AUTOSAR XML (schema 4-2-2)
package /Components
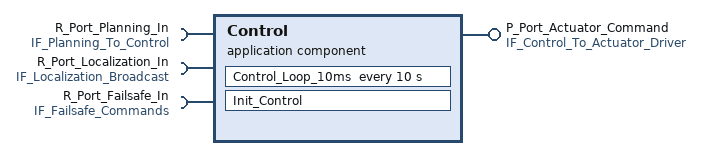
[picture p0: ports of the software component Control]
  application sw component type Control
    provide port P_Port_Actuator_Command: provided-interface=IF_Control_To_Actuator_Driver
    require port R_Port_Planning_In: required-interface=IF_Planning_To_Control
    require port R_Port_Localization_In: required-interface=IF_Localization_Broadcast
    require port R_Port_Failsafe_In: required-interface=IF_Failsafe_Commands
    behavior Control_InternalBehavior
      init event Control_Init: start-on-event=Init_Control
      timing event Control_10ms: start-on-event=Control_Loop_10ms, period=10
      runnable Init_Control: symbol=Init_Control_Symbol
        data-receive-point-by-arguments:
          access Init_Read_Behavior_Cmd: accessed-variable={autosar-variable-in-impl-datatype={port-prototype=R_Port_Planning_In, target-data-prototype=ImplType_Behavior_Cmd_Init}, autosar-variable=R_Port_Planning_In.Behavior_Cmd}
        data-send-points:
          access Init_Send_Brake_Command: accessed-variable={autosar-variable-in-impl-datatype={port-prototype=P_Port_Actuator_Command, target-data-prototype=ImplType_Brake_Command_Init}, autosar-variable=P_Port_Actuator_Command.Brake_Command}
        data-write-access:
          access Init_Write_Internal_State: accessed-variable={autosar-variable-in-impl-datatype={port-prototype=P_Port_Actuator_Command, target-data-prototype=ImplType_Internal_Control_State_Init}, autosar-variable=P_Port_Actuator_Command.Steering_Angle}
        parameter access InitParamAccess_Control_Config: accessed-parameter=R_Port_Localization_In.Localization_Status
      runnable Control_Loop_10ms: minimum-start-interval=10, symbol=Control_Loop_10ms_Symbol
        data-receive-point-by-arguments:
          access Read_Target_Trajectory: accessed-variable={autosar-variable-in-impl-datatype={port-prototype=R_Port_Planning_In, target-data-prototype=ImplType_Target_Trajectory}, autosar-variable=R_Port_Planning_In.Target_Trajectory}
          access Read_Speed_Profile: accessed-variable={autosar-variable-in-impl-datatype={port-prototype=R_Port_Planning_In, target-data-prototype=ImplType_Speed_Profile}, autosar-variable=R_Port_Planning_In.Speed_Profile}
          access Read_Behavior_Cmd: accessed-variable={autosar-variable-in-impl-datatype={port-prototype=R_Port_Planning_In, target-data-prototype=ImplType_Behavior_Cmd}, autosar-variable=R_Port_Planning_In.Behavior_Cmd}
        data-send-points:
          access Send_Steering_Angle: accessed-variable={autosar-variable-in-impl-datatype={port-prototype=P_Port_Actuator_Command, target-data-prototype=ImplType_Steering_Angle}, autosar-variable=P_Port_Actuator_Command.Steering_Angle}
          access Send_Throttle_Command: accessed-variable={autosar-variable-in-impl-datatype={port-prototype=P_Port_Actuator_Command, target-data-prototype=ImplType_Throttle_Command}, autosar-variable=P_Port_Actuator_Command.Throttle_Command}
          access Send_Brake_Command: accessed-variable={autosar-variable-in-impl-datatype={port-prototype=P_Port_Actuator_Command, target-data-prototype=ImplType_Brake_Command}, autosar-variable=P_Port_Actuator_Command.Brake_Command}
        data-write-access:
          access Write_Internal_Steering_Angle: accessed-variable={autosar-variable-in-impl-datatype={port-prototype=P_Port_Actuator_Command, target-data-prototype=ImplType_Internal_Steering_Angle_State}, autosar-variable=P_Port_Actuator_Command.Steering_Angle}
          access Write_Internal_Throttle_Command: accessed-variable={autosar-variable-in-impl-datatype={port-prototype=P_Port_Actuator_Command, target-data-prototype=ImplType_Internal_Throttle_State}, autosar-variable=P_Port_Actuator_Command.Throttle_Command}
          access Write_Internal_Brake_Command: accessed-variable={autosar-variable-in-impl-datatype={port-prototype=P_Port_Actuator_Command, target-data-prototype=ImplType_Internal_Brake_State}, autosar-variable=P_Port_Actuator_Command.Brake_Command}
        parameter access RuntimeParamAccess_Localization_Status: accessed-parameter=R_Port_Localization_In.Localization_Status
